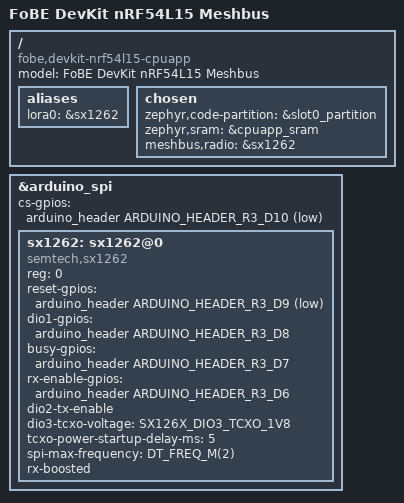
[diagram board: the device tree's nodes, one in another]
/*
 * Copyright (c) 2026 FoBE Studio
 *
 * SPDX-License-Identifier: Apache-2.0
 */

#include <nordic/nrf54l15_cpuapp.dtsi>
#include <zephyr/dt-bindings/gpio/arduino-header-r3.h>
#include <zephyr/dt-bindings/lora/sx126x.h>
#include "nrf54l15_cpuapp_common.dtsi"

/ {
	compatible = "fobe,devkit-nrf54l15-cpuapp";
	model = "FoBE DevKit nRF54L15 Meshbus";

	aliases {
		lora0 = &sx1262;
	};

	chosen {
		zephyr,code-partition = &slot0_partition;
		zephyr,sram = &cpuapp_sram;
		meshbus,radio = &sx1262;
	};
};

&arduino_spi {
	cs-gpios = <&arduino_header ARDUINO_HEADER_R3_D10 GPIO_ACTIVE_LOW>;

	sx1262: sx1262@0 {
		compatible = "semtech,sx1262";
		reg = <0>;
		reset-gpios = <&arduino_header ARDUINO_HEADER_R3_D9 GPIO_ACTIVE_LOW>;
		dio1-gpios = <&arduino_header ARDUINO_HEADER_R3_D8 GPIO_ACTIVE_HIGH>;
		busy-gpios = <&arduino_header ARDUINO_HEADER_R3_D7 GPIO_ACTIVE_HIGH>;
		rx-enable-gpios = <&arduino_header ARDUINO_HEADER_R3_D6 GPIO_ACTIVE_HIGH>;
		dio2-tx-enable;
		dio3-tcxo-voltage = <SX126X_DIO3_TCXO_1V8>;
		tcxo-power-startup-delay-ms = <5>;
		spi-max-frequency = <DT_FREQ_M(2)>;
		rx-boosted;
	};
};
